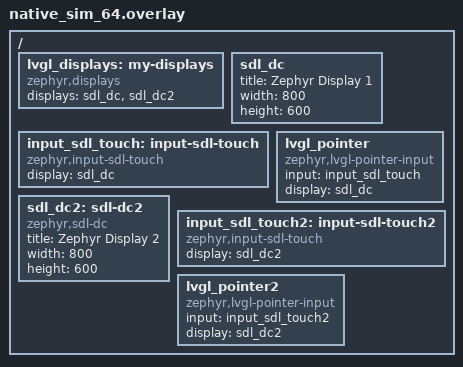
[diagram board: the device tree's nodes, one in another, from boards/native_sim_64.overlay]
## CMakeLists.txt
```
# Copyright (c) 2023 Fabian Blatz <fabianblatz@gmail.com>
# Copyright (c) 2025 Abderrahmane JARMOUNI
# SPDX-License-Identifier: Apache-2.0

cmake_minimum_required(VERSION 3.28.0)

find_package(Zephyr REQUIRED HINTS $ENV{ZEPHYR_BASE})
project(lvgl_multi_display)

set(LVGL_DIR ${ZEPHYR_LVGL_MODULE_DIR})

FILE(GLOB app_sources src/*.c)
target_sources(app PRIVATE
    ${app_sources}
    ${LVGL_DIR}/demos/lv_demos.c
)

target_include_directories(app PRIVATE
    ${LVGL_DIR}/demos/
)

target_sources_ifdef(CONFIG_LV_USE_DEMO_MUSIC app PRIVATE
    ${LVGL_DIR}/demos/music/assets/img_lv_demo_music_btn_corner_large.c
    ${LVGL_DIR}/demos/music/assets/img_lv_demo_music_btn_list_pause.c
    ${LVGL_DIR}/demos/music/assets/img_lv_demo_music_btn_list_pause_large.c
    ${LVGL_DIR}/demos/music/assets/img_lv_demo_music_btn_list_play.c
    ${LVGL_DIR}/demos/music/assets/img_lv_demo_music_btn_list_play_large.c
    ${LVGL_DIR}/demos/music/assets/img_lv_demo_music_btn_loop.c
    ${LVGL_DIR}/demos/music/assets/img_lv_demo_music_btn_loop_large.c
    ${LVGL_DIR}/demos/music/assets/img_lv_demo_music_btn_next.c
    ${LVGL_DIR}/demos/music/assets/img_lv_demo_music_btn_next_large.c
    ${LVGL_DIR}/demos/music/assets/img_lv_demo_music_btn_pause.c
    ${LVGL_DIR}/demos/music/assets/img_lv_demo_music_btn_pause_large.c
    ${LVGL_DIR}/demos/music/assets/img_lv_demo_music_btn_play.c
    ${LVGL_DIR}/demos/music/assets/img_lv_demo_music_btn_play_large.c
    ${LVGL_DIR}/demos/music/assets/img_lv_demo_music_btn_prev.c
    ${LVGL_DIR}/demos/music/assets/img_lv_demo_music_btn_prev_large.c
    ${LVGL_DIR}/demos/music/assets/img_lv_demo_music_btn_rnd.c
    ${LVGL_DIR}/demos/music/assets/img_lv_demo_music_btn_rnd_large.c
    ${LVGL_DIR}/demos/music/assets/img_lv_demo_music_corner_left.c
    ${LVGL_DIR}/demos/music/assets/img_lv_demo_music_corner_left_large.c
    ${LVGL_DIR}/demos/music/assets/img_lv_demo_music_corner_right.c
    ${LVGL_DIR}/demos/music/assets/img_lv_demo_music_corner_right_large.c
    ${LVGL_DIR}/demos/music/assets/img_lv_demo_music_cover_1.c
    ${LVGL_DIR}/demos/music/assets/img_lv_demo_music_cover_1_large.c
    ${LVGL_DIR}/demos/music/assets/img_lv_demo_music_cover_2.c
    ${LVGL_DIR}/demos/music/assets/img_lv_demo_music_cover_2_large.c
    ${LVGL_DIR}/demos/music/assets/img_lv_demo_music_cover_3.c
    ${LVGL_DIR}/demos/music/assets/img_lv_demo_music_cover_3_large.c
    ${LVGL_DIR}/demos/music/assets/img_lv_demo_music_icon_1.c
    ${LVGL_DIR}/demos/music/assets/img_lv_demo_music_icon_1_large.c
    ${LVGL_DIR}/demos/music/assets/img_lv_demo_music_icon_2.c
    ${LVGL_DIR}/demos/music/assets/img_lv_demo_music_icon_2_large.c
    ${LVGL_DIR}/demos/music/assets/img_lv_demo_music_icon_3.c
    ${LVGL_DIR}/demos/music/assets/img_lv_demo_music_icon_3_large.c
    ${LVGL_DIR}/demos/music/assets/img_lv_demo_music_icon_4.c
    ${LVGL_DIR}/demos/music/assets/img_lv_demo_music_icon_4_large.c
    ${LVGL_DIR}/demos/music/assets/img_lv_demo_music_list_border.c
    ${LVGL_DIR}/demos/music/assets/img_lv_demo_music_list_border_large.c
    ${LVGL_DIR}/demos/music/assets/img_lv_demo_music_logo.c
    ${LVGL_DIR}/demos/music/assets/img_lv_demo_music_slider_knob.c
    ${LVGL_DIR}/demos/music/assets/img_lv_demo_music_slider_knob_large.c
    ${LVGL_DIR}/demos/music/assets/img_lv_demo_music_wave_bottom.c
    ${LVGL_DIR}/demos/music/assets/img_lv_demo_music_wave_bottom_large.c
    ${LVGL_DIR}/demos/music/assets/img_lv_demo_music_wave_top.c
    ${LVGL_DIR}/demos/music/assets/img_lv_demo_music_wave_top_large.c
    ${LVGL_DIR}/demos/music/lv_demo_music.c
    ${LVGL_DIR}/demos/music/lv_demo_music_list.c
    ${LVGL_DIR}/demos/music/lv_demo_music_main.c
)

target_sources_ifdef(CONFIG_LV_USE_DEMO_BENCHMARK app PRIVATE
    ${LVGL_DIR}/demos/benchmark/assets/img_benchmark_avatar.c
    ${LVGL_DIR}/demos/benchmark/assets/img_benchmark_lvgl_logo_argb.c
    ${LVGL_DIR}/demos/benchmark/assets/img_benchmark_lvgl_logo_rgb.c
    ${LVGL_DIR}/demos/benchmark/assets/lv_font_benchmark_montserrat_12_aligned.c
    ${LVGL_DIR}/demos/benchmark/assets/lv_font_benchmark_montserrat_14_aligned.c
    ${LVGL_DIR}/demos/benchmark/assets/lv_font_benchmark_montserrat_16_aligned.c
    ${LVGL_DIR}/demos/benchmark/assets/lv_font_benchmark_montserrat_18_aligned.c
    ${LVGL_DIR}/demos/benchmark/assets/lv_font_benchmark_montserrat_20_aligned.c
    ${LVGL_DIR}/demos/benchmark/assets/lv_font_benchmark_montserrat_24_aligned.c
    ${LVGL_DIR}/demos/benchmark/assets/lv_font_benchmark_montserrat_26_aligned.c
    ${LVGL_DIR}/demos/benchmark/lv_demo_benchmark.c
)

target_sources_ifdef(CONFIG_LV_USE_DEMO_STRESS app PRIVATE
    ${LVGL_DIR}/demos/stress/lv_demo_stress.c
)

target_sources_ifdef(CONFIG_LV_USE_DEMO_WIDGETS app PRIVATE
    ${LVGL_DIR}/demos/widgets/assets/img_clothes.c
    ${LVGL_DIR}/demos/widgets/assets/img_demo_widgets_avatar.c
    ${LVGL_DIR}/demos/widgets/assets/img_demo_widgets_needle.c
    ${LVGL_DIR}/demos/widgets/assets/img_lvgl_logo.c
    ${LVGL_DIR}/demos/widgets/lv_demo_widgets.c
    ${LVGL_DIR}/demos/widgets/lv_demo_widgets_analytics.c
    ${LVGL_DIR}/demos/widgets/lv_demo_widgets_components.c
    ${LVGL_DIR}/demos/widgets/lv_demo_widgets_profile.c
    ${LVGL_DIR}/demos/widgets/lv_demo_widgets_shop.c
)
```

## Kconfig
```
# Copyright (c) 2023 Fabian Blatz <fabianblatz@gmail.com>
# Copyright (c) 2025 Abderrahmane JARMOUNI
# SPDX-License-Identifier: Apache-2.0

choice LV_Z_DEMO_FIRST_DISP
	prompt "LVGL demo to build for 1st display"
	default LV_Z_DEMO_MUSIC_FIRST_DISP
	help
	  Demo application to build for 1st display.

config LV_Z_DEMO_MUSIC_FIRST_DISP
	bool "LVGL music demo"
	select LV_USE_DEMO_MUSIC
	help
	  Build music player demo application.

config LV_Z_DEMO_BENCHMARK_FIRST_DISP
	bool "LVGL benchmark demo"
	select LV_USE_DEMO_BENCHMARK
	select LV_USE_SYSMON
	select LV_USE_PERF_MONITOR
	help
	  Build benchmarking demo application.

config LV_Z_DEMO_STRESS_FIRST_DISP
	bool "LVGL stress demo"
	select LV_USE_DEMO_STRESS
	select LV_USE_SYSMON
	select LV_USE_PERF_MONITOR
	help
	  Build stress testing demo application.

config LV_Z_DEMO_WIDGETS_FIRST_DISP
	bool "LVGL widgets demo"
	select LV_USE_DEMO_WIDGETS
	help
	  Build widgets demo application.

endchoice

choice LV_Z_DEMO_OTHER_DISPS
	prompt "LVGL demo to build for other displays"
	default LV_Z_DEMO_WIDGETS_OTHER_DISPS
	help
	  Demo application to build for other displays.

config LV_Z_DEMO_MUSIC_OTHER_DISPS
	bool "LVGL music demo"
	select LV_USE_DEMO_MUSIC
	help
	  Build music player demo application.

config LV_Z_DEMO_BENCHMARK_OTHER_DISPS
	bool "LVGL benchmark demo"
	select LV_USE_DEMO_BENCHMARK
	select LV_USE_SYSMON
	select LV_USE_PERF_MONITOR
	help
	  Build benchmarking demo application.

config LV_Z_DEMO_STRESS_OTHER_DISPS
	bool "LVGL stress demo"
	select LV_USE_DEMO_STRESS
	select LV_USE_SYSMON
	select LV_USE_PERF_MONITOR
	help
	  Build stress testing demo application.

config LV_Z_DEMO_WIDGETS_OTHER_DISPS
	bool "LVGL widgets demo"
	select LV_USE_DEMO_WIDGETS
	help
	  Build widgets demo application.

endchoice

configdefault CPU_LOAD
	default y if LV_USE_SYSMON

source "Kconfig.zephyr"
```

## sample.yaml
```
sample:
  description: LVGL multi-display sample
  name: LVGL Multi-display
common:
  modules:
    - lvgl
  filter: dt_compat_enabled("zephyr,displays")
  tags:
    - samples
    - display
    - lvgl
    - gui
  harness_config:
    fixture: fixture_display
tests:
  sample.modules.lvgl.multi_display:
    integration_platforms:
      - native_sim/native/64
```

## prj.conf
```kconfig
CONFIG_MAIN_STACK_SIZE=4096
CONFIG_LOG=y

CONFIG_DISPLAY=y

CONFIG_LVGL=y
CONFIG_LV_USE_LOG=y
CONFIG_LV_Z_MEM_POOL_SIZE=116736
CONFIG_SYS_HEAP_RUNTIME_STATS=y

CONFIG_LV_FONT_MONTSERRAT_12=y
CONFIG_LV_FONT_MONTSERRAT_14=y
CONFIG_LV_FONT_MONTSERRAT_16=y
CONFIG_LV_FONT_MONTSERRAT_18=y
CONFIG_LV_FONT_MONTSERRAT_24=y

# Benchmark Demo
CONFIG_LV_USE_FONT_COMPRESSED=y
```

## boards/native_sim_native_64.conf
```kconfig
# Copyright 2025 Abderrahmane JARMOUNI
# SPDX-License-Identifier: Apache-2.0

CONFIG_LV_COLOR_FORMAT_XRGB8888=y
CONFIG_LV_Z_MEM_POOL_SIZE=150536

CONFIG_INPUT=y
```

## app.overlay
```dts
/*
 * Copyright (c) 2025, Abderrahmane JARMOUNI
 *
 * SPDX-License-Identifier: Apache-2.0
 */

/ {
	/delete-property/ zephyr,display;
};
```

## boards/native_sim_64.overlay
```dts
/*
 * Copyright (c) 2025, Abderrahmane JARMOUNI
 *
 * SPDX-License-Identifier: Apache-2.0
 */

/ {
	lvgl_displays: my-displays {
		compatible = "zephyr,displays";
		displays = <&sdl_dc &sdl_dc2>;
		status = "okay";
	};

	sdl_dc {
		title = "Zephyr Display 1";
		width = <800>;
		height = <600>;
		status = "okay";
	};

	input_sdl_touch: input-sdl-touch {
		compatible = "zephyr,input-sdl-touch";
		display = <&sdl_dc>;
	};

	lvgl_pointer {
		compatible = "zephyr,lvgl-pointer-input";
		input = <&input_sdl_touch>;
		display = <&sdl_dc>;
		status = "okay";
	};

	sdl_dc2: sdl-dc2 {
		compatible = "zephyr,sdl-dc";
		title = "Zephyr Display 2";
		width = <800>;
		height = <600>;
		status = "okay";
	};

	input_sdl_touch2: input-sdl-touch2 {
		compatible = "zephyr,input-sdl-touch";
		display = <&sdl_dc2>;
	};

	lvgl_pointer2 {
		compatible = "zephyr,lvgl-pointer-input";
		input = <&input_sdl_touch2>;
		display = <&sdl_dc2>;
		status = "okay";
	};
};
```

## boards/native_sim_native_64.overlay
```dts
/*
 * Copyright (c) 2025, Abderrahmane JARMOUNI
 *
 * SPDX-License-Identifier: Apache-2.0
 */

/ {
	lvgl_displays: my-displays {
		compatible = "zephyr,displays";
		displays = <&sdl_dc &sdl_dc2>;
		status = "okay";
	};

	sdl_dc {
		title = "Zephyr Display 1";
		width = <800>;
		height = <600>;
		status = "okay";
	};

	input_sdl_touch: input-sdl-touch {
		compatible = "zephyr,input-sdl-touch";
		display = <&sdl_dc>;
	};

	lvgl_pointer {
		compatible = "zephyr,lvgl-pointer-input";
		input = <&input_sdl_touch>;
		display = <&sdl_dc>;
		status = "okay";
	};

	sdl_dc2: sdl-dc2 {
		compatible = "zephyr,sdl-dc";
		title = "Zephyr Display 2";
		pixel-format = "PANEL_PIXEL_FORMAT_ARGB_8888";
		width = <800>;
		height = <600>;
		status = "okay";
	};

	input_sdl_touch2: input-sdl-touch2 {
		compatible = "zephyr,input-sdl-touch";
		display = <&sdl_dc2>;
	};

	lvgl_pointer2 {
		compatible = "zephyr,lvgl-pointer-input";
		input = <&input_sdl_touch2>;
		display = <&sdl_dc2>;
		status = "okay";
	};
};
```

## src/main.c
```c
/*
 * Copyright (c) 2025 Abderrahmane JARMOUNI
 *
 * SPDX-License-Identifier: Apache-2.0
 */

#include <zephyr/kernel.h>
#include <zephyr/drivers/display.h>
#include <lvgl.h>
#include <lvgl_mem.h>
#include <lv_demos.h>
#include <stdio.h>
#include <lvgl_zephyr.h>

#define LOG_LEVEL CONFIG_LOG_DEFAULT_LEVEL
#include <zephyr/logging/log.h>
LOG_MODULE_REGISTER(app);

#if !DT_HAS_COMPAT_STATUS_OKAY(zephyr_displays)
#error Could not find "zephyr,displays" compatible node in DT
#endif

#define ENUMERATE_DISPLAY_DEVS(n) display_dev[n] = DEVICE_DT_GET(DT_ZEPHYR_DISPLAY(n));

int main(void)
{
	const struct device *display_dev[DT_ZEPHYR_DISPLAYS_COUNT];
	lv_display_t *lv_displays[DT_ZEPHYR_DISPLAYS_COUNT];
	lv_display_t *d = NULL;

	/* clang-format off */
	FOR_EACH(ENUMERATE_DISPLAY_DEVS, (), LV_DISPLAYS_IDX_LIST);
	/* clang-format on */

	for (int i = 0; i < DT_ZEPHYR_DISPLAYS_COUNT; i++) {
		if (!device_is_ready(display_dev[i])) {
			LOG_ERROR("Display device %d is not ready", i);
			return 0;
		}
	}

	for (int i = 0; i < DT_ZEPHYR_DISPLAYS_COUNT; i++) {
		d = lv_display_get_next(d);
		if (d == NULL) {
			LOG_ERROR("Invalid LV display %d object", i);
			return 0;
		}
		lv_displays[i] = d;
	}

	lv_display_set_default(lv_displays[0]);
#ifdef CONFIG_LV_Z_DEMO_MUSIC_FIRST_DISP
	lv_demo_music();
#elif defined(CONFIG_LV_Z_DEMO_BENCHMARK_FIRST_DISP)
	lv_demo_benchmark();
#elif defined(CONFIG_LV_Z_DEMO_STRESS_FIRST_DISP)
	lv_demo_stress();
#elif defined(CONFIG_LV_Z_DEMO_WIDGETS_FIRST_DISP)
	lv_demo_widgets();
#endif

#if DT_ZEPHYR_DISPLAYS_COUNT > 1
	for (int i = 1; i < DT_ZEPHYR_DISPLAYS_COUNT; i++) {
		lv_display_set_default(lv_displays[i]);
#ifdef CONFIG_LV_Z_DEMO_MUSIC_OTHER_DISPS
		lv_demo_music();
#elif defined(CONFIG_LV_Z_DEMO_BENCHMARK_OTHER_DISPS)
		lv_demo_benchmark();
#elif defined(CONFIG_LV_Z_DEMO_STRESS_OTHER_DISPS)
		lv_demo_stress();
#elif defined(CONFIG_LV_Z_DEMO_WIDGETS_OTHER_DISPS)
		lv_demo_widgets();
#endif
	}
#endif

	lv_timer_handler();
	for (int i = 0; i < DT_ZEPHYR_DISPLAYS_COUNT; i++) {
		int ret;

		ret = display_blanking_off(display_dev[i]);
		if (ret < 0 && ret != -ENOSYS) {
			LOG_ERROR("Failed to turn display %s blanking off (error %d)",
				  display_dev[i]->name, ret);
			return 0;
		}
	}

#ifdef CONFIG_LV_Z_MEM_POOL_SYS_HEAP
	lvgl_print_heap_info(false);
#else
	printf("lvgl in malloc mode\n");
#endif
	while (1) {
		uint32_t sleep_ms = lv_timer_handler();

		k_msleep(MIN(sleep_ms, INT32_MAX));
	}

	return 0;
}
```
